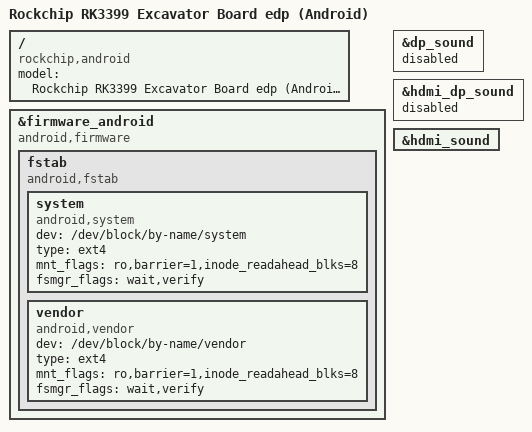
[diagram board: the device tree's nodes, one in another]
// SPDX-License-Identifier: (GPL-2.0+ OR MIT)
/*
 * Copyright (c) 2022 Rockchip Electronics Co., Ltd.
 *
 */

/dts-v1/;
#include "rk3399-sapphire-excavator-edp.dtsi"

/ {
	model = "Rockchip RK3399 Excavator Board edp (Android)";
	compatible = "rockchip,android", "rockchip,rk3399-excavator-edp", "rockchip,rk3399";
};

&firmware_android {
	compatible = "android,firmware";
	fstab {
		compatible = "android,fstab";
		system {
			compatible = "android,system";
			dev = "/dev/block/by-name/system";
			type = "ext4";
			mnt_flags = "ro,barrier=1,inode_readahead_blks=8";
			fsmgr_flags = "wait,verify";
		};
		vendor {
			compatible = "android,vendor";
			dev = "/dev/block/by-name/vendor";
			type = "ext4";
			mnt_flags = "ro,barrier=1,inode_readahead_blks=8";
			fsmgr_flags = "wait,verify";
		};
	};
};

&dp_sound {
	status = "disabled";
};

&hdmi_dp_sound {
	status = "disabled";
};

&hdmi_sound {
	status = "okay";
};
